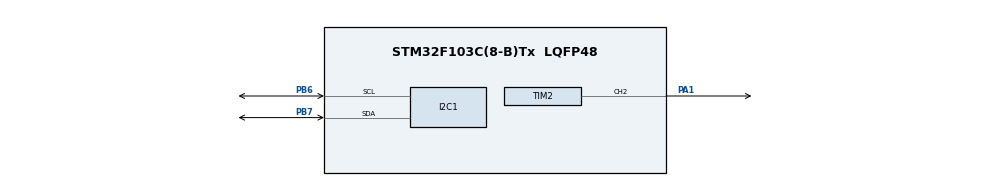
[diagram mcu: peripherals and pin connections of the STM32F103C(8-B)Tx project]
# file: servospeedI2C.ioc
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I2C1.I2C_Mode=I2C_Fast
Mcu.Family=STM32F1
Mcu.Name=STM32F103C(8-B)Tx
Mcu.Package=LQFP48
NVIC.PriorityGroup=NVIC_PRIORITYGROUP_4
PA1.Signal=S_TIM2_CH2
PA13.Mode=Serial_Wire
PA13.Signal=SYS_JTMS-SWDIO
PA14.Mode=Serial_Wire
PA14.Signal=SYS_JTCK-SWCLK
PB6.Mode=I2C
PB6.Signal=I2C1_SCL
PB7.Mode=I2C
PB7.Signal=I2C1_SDA
ProjectManager.HeapSize=0x200
ProjectManager.StackSize=0x400
ProjectManager.TargetToolchain=MDK-ARM V5.32
RCC.APB1Freq_Value=8000000
RCC.APB2Freq_Value=8000000
SH.S_TIM2_CH2.0=TIM2_CH2,PWM Generation2 CH2
TIM2.Channel-PWM\ Generation2\ CH2=TIM_CHANNEL_2
TIM2.Period=9999
TIM2.Prescaler=15
VP_TIM2_VS_ClockSourceINT.Mode=Internal
board=custom

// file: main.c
/* USER CODE BEGIN Header */
/**
  ******************************************************************************
  * @file           : main.c
  * @brief          : Fan Speed Controller � Servo + OLED Display
  *                   STM32 Bluepill + Continuous Servo + SSD1306 I2C
  ******************************************************************************
  */
/* USER CODE END Header */
#include "main.h"

/* USER CODE BEGIN Includes */
#include <stdio.h>
#include <string.h>
#include "ssd1306.h"
#include "ssd1306_fonts.h"
/* USER CODE END Includes */

I2C_HandleTypeDef hi2c1;

TIM_HandleTypeDef htim2;

/* USER CODE BEGIN PV */
#define STAGE_COUNT        5
#define STAGE_HOLD_TIME_MS 10000

#define SERVO_STOP      1500
#define SERVO_MIN_PULSE 500
#define SERVO_MAX_PULSE 2500

typedef struct {
    uint16_t pulse;
    const char *label;
    const char *direction;
    uint8_t percent;
} ServoStage;

static const ServoStage stages[STAGE_COUNT] = {
    { 1500, "STOP",  "---", 0   },
    { 1700, "LOW",   "CW",  25  },
    { 1900, "MED",   "CW",  50  },
    { 2100, "HIGH",  "CW",  75  },
    { 2500, "MAX",   "CW",  100 }
};

static uint8_t  currentStage    = 0;
static uint8_t  direction       = 1;
static uint32_t stageStartTick  = 0;
static uint32_t totalRunSeconds = 0;
static uint32_t lastSecondTick  = 0;
/* USER CODE END PV */

void SystemClock_Config(void);
static void MX_GPIO_Init(void);
static void MX_I2C1_Init(void);
static void MX_TIM2_Init(void);

/* USER CODE BEGIN PFP */
void OLED_ShowStatus(uint32_t remainingSec);
/* USER CODE END PFP */

/* USER CODE BEGIN 0 */

void Servo_SetPulse(uint16_t pulse)
{
    __HAL_TIM_SET_COMPARE(&htim2, TIM_CHANNEL_2, pulse);
}

void OLED_ShowStatus(uint32_t remainingSec)
{
    char line[24];

    ssd1306_Fill(Black);

    ssd1306_SetCursor(0, 0);
    ssd1306_WriteString("  Servo Fan System", Font_7x10, White);

    ssd1306_SetCursor(0, 14);
    sprintf(line, "Mode : %-5s %3u%%",
            stages[currentStage].label,
            stages[currentStage].percent);
    ssd1306_WriteString(line, Font_7x10, White);

    ssd1306_SetCursor(0, 28);
    sprintf(line, "Dir  : %s",
            stages[currentStage].direction);
    ssd1306_WriteString(line, Font_7x10, White);

    ssd1306_SetCursor(0, 42);
    sprintf(line, "PWM  : %4u", stages[currentStage].pulse);
    ssd1306_WriteString(line, Font_7x10, White);

    ssd1306_SetCursor(0, 54);
    sprintf(line, "Next : %2us %s",
            (unsigned)remainingSec,
            direction ? "UP" : "DN");
    ssd1306_WriteString(line, Font_7x10, White);

    ssd1306_UpdateScreen();
}

/* USER CODE END 0 */

int main(void)
{

  /* MCU Configuration--------------------------------------------------------*/

  /* Reset of all peripherals, Initializes the Flash interface and the Systick. */
  HAL_Init();

  /* Configure the system clock */
  SystemClock_Config();

  /* Initialize all configured peripherals */
  MX_GPIO_Init();
  MX_I2C1_Init();
  MX_TIM2_Init();
  /* USER CODE BEGIN 2 */
    HAL_TIM_PWM_Start(&htim2, TIM_CHANNEL_2);

    ssd1306_Init();
    ssd1306_Fill(Black);
    ssd1306_SetCursor(8, 20);
    ssd1306_WriteString(" ServoControl is", Font_7x10, White);
    ssd1306_SetCursor(28, 36);
    ssd1306_WriteString("starting...", Font_7x10, White);
    ssd1306_UpdateScreen();
    HAL_Delay(1500);

    currentStage    = 0;
    direction       = 1;
    stageStartTick  = HAL_GetTick();
    lastSecondTick  = HAL_GetTick();
    totalRunSeconds = 0;

    Servo_SetPulse(stages[currentStage].pulse);
  /* USER CODE END 2 */

  /* Infinite loop */
  /* USER CODE BEGIN WHILE */
  while (1)
  {
        uint32_t now = HAL_GetTick();

        if ((now - lastSecondTick) >= 1000)
        {
            totalRunSeconds++;
            lastSecondTick += 1000;
        }

        uint32_t elapsed   = now - stageStartTick;
        uint32_t remaining = (elapsed >= STAGE_HOLD_TIME_MS)
                             ? 0
                             : (STAGE_HOLD_TIME_MS - elapsed) / 1000;

        if (elapsed >= STAGE_HOLD_TIME_MS)
        {
            if (direction == 1)
            {
                if (currentStage < STAGE_COUNT - 1)
                    currentStage++;
                else
                {
                    direction = 0;
                    currentStage--;
                }
            }
            else
            {
                if (currentStage > 0)
                    currentStage--;
                else
                {
                    direction = 1;
                    currentStage++;
                }
            }

            Servo_SetPulse(stages[currentStage].pulse);
            stageStartTick = now;
            remaining      = STAGE_HOLD_TIME_MS / 1000;
        }

        static uint32_t lastDisplayTick = 0;
        if ((now - lastDisplayTick) >= 500)
        {
            OLED_ShowStatus(remaining);
            lastDisplayTick = now;
        }
    /* USER CODE END WHILE */

  }
}

void SystemClock_Config(void)
{
  RCC_OscInitTypeDef RCC_OscInitStruct = {0};
  RCC_ClkInitTypeDef RCC_ClkInitStruct = {0};

  /** Initializes the RCC Oscillators according to the specified parameters
  * in the RCC_OscInitTypeDef structure.
  */
  RCC_OscInitStruct.OscillatorType = RCC_OSCILLATORTYPE_HSI;
  RCC_OscInitStruct.HSIState = RCC_HSI_ON;
  RCC_OscInitStruct.HSICalibrationValue = RCC_HSICALIBRATION_DEFAULT;
  RCC_OscInitStruct.PLL.PLLState = RCC_PLL_NONE;
  if (HAL_RCC_OscConfig(&RCC_OscInitStruct) != HAL_OK)
  {
    Error_Handler();
  }

  /** Initializes the CPU, AHB and APB buses clocks
  */
  RCC_ClkInitStruct.ClockType = RCC_CLOCKTYPE_HCLK|RCC_CLOCKTYPE_SYSCLK
                              |RCC_CLOCKTYPE_PCLK1|RCC_CLOCKTYPE_PCLK2;
  RCC_ClkInitStruct.SYSCLKSource = RCC_SYSCLKSOURCE_HSI;
  RCC_ClkInitStruct.AHBCLKDivider = RCC_SYSCLK_DIV1;
  RCC_ClkInitStruct.APB1CLKDivider = RCC_HCLK_DIV1;
  RCC_ClkInitStruct.APB2CLKDivider = RCC_HCLK_DIV1;

  if (HAL_RCC_ClockConfig(&RCC_ClkInitStruct, FLASH_LATENCY_0) != HAL_OK)
  {
    Error_Handler();
  }
}

static void MX_I2C1_Init(void)
{

  hi2c1.Instance = I2C1;
  hi2c1.Init.ClockSpeed = 400000;
  hi2c1.Init.DutyCycle = I2C_DUTYCYCLE_2;
  hi2c1.Init.OwnAddress1 = 0;
  hi2c1.Init.AddressingMode = I2C_ADDRESSINGMODE_7BIT;
  hi2c1.Init.DualAddressMode = I2C_DUALADDRESS_DISABLE;
  hi2c1.Init.OwnAddress2 = 0;
  hi2c1.Init.GeneralCallMode = I2C_GENERALCALL_DISABLE;
  hi2c1.Init.NoStretchMode = I2C_NOSTRETCH_DISABLE;
  if (HAL_I2C_Init(&hi2c1) != HAL_OK)
  {
    Error_Handler();
  }

}

static void MX_TIM2_Init(void)
{

  TIM_ClockConfigTypeDef sClockSourceConfig = {0};
  TIM_MasterConfigTypeDef sMasterConfig = {0};
  TIM_OC_InitTypeDef sConfigOC = {0};

  htim2.Instance = TIM2;
  htim2.Init.Prescaler = 7;
  htim2.Init.CounterMode = TIM_COUNTERMODE_UP;
  htim2.Init.Period = 19999;
  htim2.Init.ClockDivision = TIM_CLOCKDIVISION_DIV1;
  htim2.Init.AutoReloadPreload = TIM_AUTORELOAD_PRELOAD_DISABLE;
  if (HAL_TIM_Base_Init(&htim2) != HAL_OK)
  {
    Error_Handler();
  }
  sClockSourceConfig.ClockSource = TIM_CLOCKSOURCE_INTERNAL;
  if (HAL_TIM_ConfigClockSource(&htim2, &sClockSourceConfig) != HAL_OK)
  {
    Error_Handler();
  }
  if (HAL_TIM_PWM_Init(&htim2) != HAL_OK)
  {
    Error_Handler();
  }
  sMasterConfig.MasterOutputTrigger = TIM_TRGO_RESET;
  sMasterConfig.MasterSlaveMode = TIM_MASTERSLAVEMODE_DISABLE;
  if (HAL_TIMEx_MasterConfigSynchronization(&htim2, &sMasterConfig) != HAL_OK)
  {
    Error_Handler();
  }
  sConfigOC.OCMode = TIM_OCMODE_PWM1;
  sConfigOC.Pulse = 0;
  sConfigOC.OCPolarity = TIM_OCPOLARITY_HIGH;
  sConfigOC.OCFastMode = TIM_OCFAST_DISABLE;
  if (HAL_TIM_PWM_ConfigChannel(&htim2, &sConfigOC, TIM_CHANNEL_2) != HAL_OK)
  {
    Error_Handler();
  }
  HAL_TIM_MspPostInit(&htim2);

}

static void MX_GPIO_Init(void)
{

  /* GPIO Ports Clock Enable */
  __HAL_RCC_GPIOA_CLK_ENABLE();
  __HAL_RCC_GPIOB_CLK_ENABLE();

}

void Error_Handler(void)
{
  __disable_irq();
  while (1)
  {
  }
}
